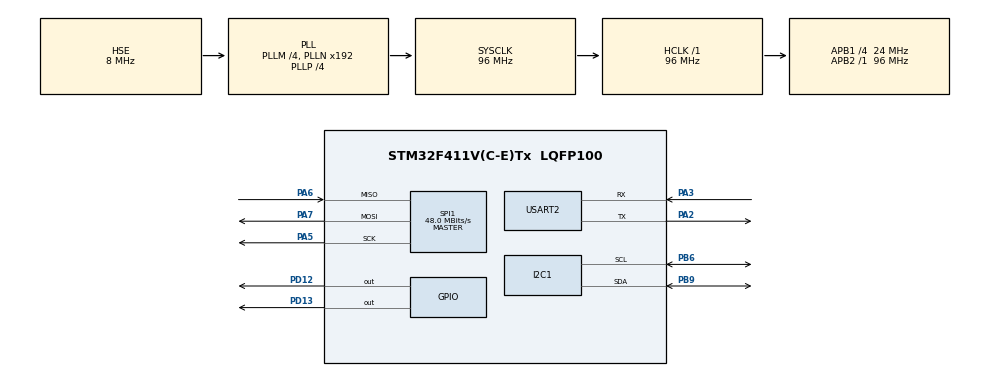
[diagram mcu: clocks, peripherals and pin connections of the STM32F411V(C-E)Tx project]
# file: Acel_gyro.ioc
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Mcu.Family=STM32F4
Mcu.Name=STM32F411V(C-E)Tx
Mcu.Package=LQFP100
NVIC.PriorityGroup=NVIC_PRIORITYGROUP_0
NVIC.RCC_IRQn=true\:0\:0\:false\:false\:true\:true\:false
NVIC.USART2_IRQn=true\:0\:0\:false\:false\:true\:true\:true
PA2.Mode=Asynchronous
PA2.Signal=USART2_TX
PA3.Mode=Asynchronous
PA3.Signal=USART2_RX
PA5.Mode=Full_Duplex_Master
PA5.Signal=SPI1_SCK
PA6.Mode=Full_Duplex_Master
PA6.Signal=SPI1_MISO
PA7.Mode=Full_Duplex_Master
PA7.Signal=SPI1_MOSI
PB6.Mode=I2C
PB6.Signal=I2C1_SCL
PB9.Mode=I2C
PB9.Signal=I2C1_SDA
PD12.Signal=GPIO_Output
PD13.Signal=GPIO_Output
PH0\ -\ OSC_IN.Mode=HSE-External-Oscillator
PH0\ -\ OSC_IN.Signal=RCC_OSC_IN
PH1\ -\ OSC_OUT.Mode=HSE-External-Oscillator
PH1\ -\ OSC_OUT.Signal=RCC_OSC_OUT
ProjectManager.HeapSize=0x200
ProjectManager.StackSize=0x400
ProjectManager.TargetToolchain=SW4STM32
RCC.48MHZClocksFreq_Value=48000000
RCC.AHBFreq_Value=96000000
RCC.APB1CLKDivider=RCC_HCLK_DIV4
RCC.APB1Freq_Value=24000000
RCC.APB1TimFreq_Value=48000000
RCC.APB2Freq_Value=96000000
RCC.APB2TimFreq_Value=96000000
RCC.CortexFreq_Value=96000000
RCC.HCLKFreq_Value=96000000
RCC.HSE_VALUE=8000000
RCC.HSI_VALUE=16000000
RCC.LSE_VALUE=32768
RCC.PLLI2SM=5
RCC.PLLI2SN=200
RCC.PLLM=4
RCC.PLLP=RCC_PLLP_DIV4
RCC.PLLQ=8
RCC.PLLSourceVirtual=RCC_PLLSOURCE_HSE
RCC.SYSCLKFreq_VALUE=96000000
RCC.SYSCLKSource=RCC_SYSCLKSOURCE_PLLCLK
RCC.VCOOutputFreq_Value=384000000
SPI1.CalculateBaudRate=48.0 MBits/s
SPI1.Direction=SPI_DIRECTION_2LINES
SPI1.Mode=SPI_MODE_MASTER
SPI1.VirtualType=VM_MASTER
USART2.VirtualMode=VM_ASYNC
board=STM32F411E-DISCO

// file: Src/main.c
/* USER CODE BEGIN Header */
/**
  ******************************************************************************
  * @file           : main.c
  * @brief          : Main program body
  ******************************************************************************
  * @attention
  *
  * <h2><center>&copy; Copyright (c) 2019 STMicroelectronics.
  * All rights reserved.</center></h2>
  *
  * This software component is licensed by ST under BSD 3-Clause license,
  * the "License"; You may not use this file except in compliance with the
  * License. You may obtain a copy of the License at:
  *                        opensource.org/licenses/BSD-3-Clause
  *
  ******************************************************************************
  */
/* USER CODE END Header */

#include "stdio.h"
#include "main.h"
#include "gyro.h"
#include "l3gd20.h"
#include "string.h"
#include "stm32f411e_discovery_accelerometer.h"
#include "stm32f411e_discovery_gyroscope.h"

I2C_HandleTypeDef hi2c1;

SPI_HandleTypeDef hspi1;

UART_HandleTypeDef huart2;
uint32_t GyrData[3];
uint32_t AclData[3];
/* USER CODE BEGIN PV */
uint32_t Gyrx;
uint32_t Gyry;
uint32_t Gyrz;
uint32_t Aclx;
uint32_t Acly;
uint32_t Aclz;

/* USER CODE END PV */

void SystemClock_Config(void);
static void MX_GPIO_Init(void);
static void MX_I2C1_Init(void);
static void MX_SPI1_Init(void);
static void MX_USART2_UART_Init(void);

int main(void)
{

  /* MCU Configuration--------------------------------------------------------*/

  /* Reset of all peripherals, Initializes the Flash interface and the Systick. */
  HAL_Init();

  /* Configure the system clock */
  SystemClock_Config();

  BSP_GYRO_Init();
  BSP_ACCELERO_Init();
  /* Initialize all configured peripherals */
  MX_GPIO_Init();
  MX_I2C1_Init();
  MX_SPI1_Init();
  MX_USART2_UART_Init();
  /* USER CODE BEGIN 2 */
  BSP_GYRO_ReadID();

  /* USER CODE END 2 */

  /* Infinite loop */
  while (1)
  {
	  BSP_GYRO_GetXYZ(GyrData);
	  Gyrx = GyrData[0];
	  Gyry = GyrData[1];
	  Gyrz = GyrData[2];
	  Aclx = AclData[0];
	  Acly = AclData[1];
	  Aclz = AclData[2];
	  BSP_ACCELERO_GetXYZ(AclData);
	  HAL_GPIO_TogglePin(GPIOD,GPIO_PIN_13);
	  HAL_Delay(1000);
  }
}

void SystemClock_Config(void)
{
  RCC_OscInitTypeDef RCC_OscInitStruct = {0};
  RCC_ClkInitTypeDef RCC_ClkInitStruct = {0};

  /** Configure the main internal regulator output voltage
  */
  __HAL_RCC_PWR_CLK_ENABLE();
  __HAL_PWR_VOLTAGESCALING_CONFIG(PWR_REGULATOR_VOLTAGE_SCALE1);
  /** Initializes the CPU, AHB and APB busses clocks
  */
  RCC_OscInitStruct.OscillatorType = RCC_OSCILLATORTYPE_HSE;
  RCC_OscInitStruct.HSEState = RCC_HSE_ON;
  RCC_OscInitStruct.PLL.PLLState = RCC_PLL_ON;
  RCC_OscInitStruct.PLL.PLLSource = RCC_PLLSOURCE_HSE;
  RCC_OscInitStruct.PLL.PLLM = 4;
  RCC_OscInitStruct.PLL.PLLN = 192;
  RCC_OscInitStruct.PLL.PLLP = RCC_PLLP_DIV4;
  RCC_OscInitStruct.PLL.PLLQ = 8;
  if (HAL_RCC_OscConfig(&RCC_OscInitStruct) != HAL_OK)
  {
    Error_Handler();
  }
  /** Initializes the CPU, AHB and APB busses clocks
  */
  RCC_ClkInitStruct.ClockType = RCC_CLOCKTYPE_HCLK|RCC_CLOCKTYPE_SYSCLK
                              |RCC_CLOCKTYPE_PCLK1|RCC_CLOCKTYPE_PCLK2;
  RCC_ClkInitStruct.SYSCLKSource = RCC_SYSCLKSOURCE_PLLCLK;
  RCC_ClkInitStruct.AHBCLKDivider = RCC_SYSCLK_DIV1;
  RCC_ClkInitStruct.APB1CLKDivider = RCC_HCLK_DIV4;
  RCC_ClkInitStruct.APB2CLKDivider = RCC_HCLK_DIV1;

  if (HAL_RCC_ClockConfig(&RCC_ClkInitStruct, FLASH_LATENCY_3) != HAL_OK)
  {
    Error_Handler();
  }
}

static void MX_I2C1_Init(void)
{

  hi2c1.Instance = I2C1;
  hi2c1.Init.ClockSpeed = 100000;
  hi2c1.Init.DutyCycle = I2C_DUTYCYCLE_2;
  hi2c1.Init.OwnAddress1 = 0;
  hi2c1.Init.AddressingMode = I2C_ADDRESSINGMODE_7BIT;
  hi2c1.Init.DualAddressMode = I2C_DUALADDRESS_DISABLE;
  hi2c1.Init.OwnAddress2 = 0;
  hi2c1.Init.GeneralCallMode = I2C_GENERALCALL_DISABLE;
  hi2c1.Init.NoStretchMode = I2C_NOSTRETCH_DISABLE;
  if (HAL_I2C_Init(&hi2c1) != HAL_OK)
  {
    Error_Handler();
  }

}

static void MX_SPI1_Init(void)
{

  /* SPI1 parameter configuration*/
  hspi1.Instance = SPI1;
  hspi1.Init.Mode = SPI_MODE_MASTER;
  hspi1.Init.Direction = SPI_DIRECTION_2LINES;
  hspi1.Init.DataSize = SPI_DATASIZE_8BIT;
  hspi1.Init.CLKPolarity = SPI_POLARITY_LOW;
  hspi1.Init.CLKPhase = SPI_PHASE_1EDGE;
  hspi1.Init.NSS = SPI_NSS_SOFT;
  hspi1.Init.BaudRatePrescaler = SPI_BAUDRATEPRESCALER_2;
  hspi1.Init.FirstBit = SPI_FIRSTBIT_MSB;
  hspi1.Init.TIMode = SPI_TIMODE_DISABLE;
  hspi1.Init.CRCCalculation = SPI_CRCCALCULATION_DISABLE;
  hspi1.Init.CRCPolynomial = 10;
  if (HAL_SPI_Init(&hspi1) != HAL_OK)
  {
    Error_Handler();
  }

}

static void MX_USART2_UART_Init(void)
{

  huart2.Instance = USART2;
  huart2.Init.BaudRate = 115200;
  huart2.Init.WordLength = UART_WORDLENGTH_8B;
  huart2.Init.StopBits = UART_STOPBITS_1;
  huart2.Init.Parity = UART_PARITY_NONE;
  huart2.Init.Mode = UART_MODE_TX_RX;
  huart2.Init.HwFlowCtl = UART_HWCONTROL_NONE;
  huart2.Init.OverSampling = UART_OVERSAMPLING_16;
  if (HAL_UART_Init(&huart2) != HAL_OK)
  {
    Error_Handler();
  }

}

static void MX_GPIO_Init(void)
{
  GPIO_InitTypeDef GPIO_InitStruct = {0};

  /* GPIO Ports Clock Enable */
  __HAL_RCC_GPIOH_CLK_ENABLE();
  __HAL_RCC_GPIOA_CLK_ENABLE();
  __HAL_RCC_GPIOD_CLK_ENABLE();
  __HAL_RCC_GPIOB_CLK_ENABLE();

  /*Configure GPIO pin Output Level */
  HAL_GPIO_WritePin(GPIOD, GPIO_PIN_12|GPIO_PIN_13, GPIO_PIN_RESET);

  /*Configure GPIO pins : PD12 PD13 */
  GPIO_InitStruct.Pin = GPIO_PIN_12|GPIO_PIN_13;
  GPIO_InitStruct.Mode = GPIO_MODE_OUTPUT_PP;
  GPIO_InitStruct.Pull = GPIO_NOPULL;
  GPIO_InitStruct.Speed = GPIO_SPEED_FREQ_LOW;
  HAL_GPIO_Init(GPIOD, &GPIO_InitStruct);

}

void Error_Handler(void)
{
}

/************************ (C) COPYRIGHT STMicroelectronics *****END OF FILE****/
